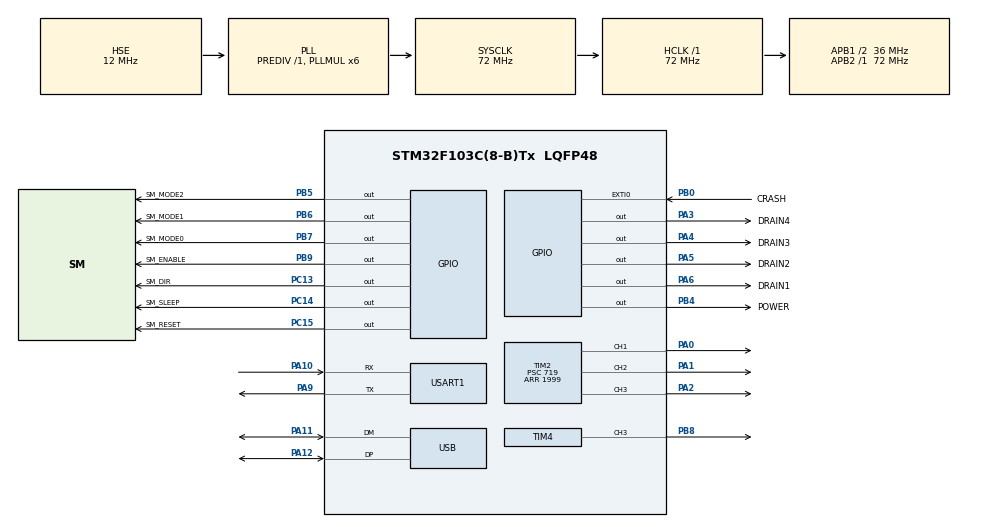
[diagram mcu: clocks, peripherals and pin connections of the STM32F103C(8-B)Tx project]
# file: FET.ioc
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Mcu.Family=STM32F1
Mcu.Name=STM32F103C(8-B)Tx
Mcu.Package=LQFP48
NVIC.EXTI0_IRQn=true\:2\:0\:true\:false\:true
NVIC.PriorityGroup=NVIC_PRIORITYGROUP_4
NVIC.TIM4_IRQn=true\:0\:0\:false\:false\:true
NVIC.USB_LP_CAN1_RX0_IRQn=true\:0\:0\:false\:false\:true
PA0-WKUP.Signal=S_TIM2_CH1_ETR
PA1.Signal=S_TIM2_CH2
PA10.Mode=Asynchronous
PA10.Signal=USART1_RX
PA11.Mode=Device
PA11.Signal=USB_DM
PA12.Mode=Device
PA12.Signal=USB_DP
PA13.Mode=Serial_Wire
PA13.Signal=SYS_JTMS-SWDIO
PA14.Mode=Serial_Wire
PA14.Signal=SYS_JTCK-SWCLK
PA2.Signal=S_TIM2_CH3
PA3.GPIO_Label=DRAIN4
PA3.Signal=GPIO_Output
PA4.GPIO_Label=DRAIN3
PA4.Signal=GPIO_Output
PA5.GPIO_Label=DRAIN2
PA5.Signal=GPIO_Output
PA6.GPIO_Label=DRAIN1
PA6.Signal=GPIO_Output
PA9.Mode=Asynchronous
PA9.Signal=USART1_TX
PB0.GPIO_Label=CRASH
PB0.GPIO_ModeDefaultEXTI=GPIO_MODE_IT_FALLING
PB0.GPIO_PuPd=GPIO_PULLUP
PB0.Signal=GPXTI0
PB4.GPIO_Label=POWER
PB4.Signal=GPIO_Output
PB5.GPIO_Label=SM_MODE2
PB5.Signal=GPIO_Output
PB6.GPIO_Label=SM_MODE1
PB6.Signal=GPIO_Output
PB7.GPIO_Label=SM_MODE0
PB7.Signal=GPIO_Output
PB8.Signal=S_TIM4_CH3
PB9.GPIO_Label=SM_ENABLE
PB9.Signal=GPIO_Output
PC13-TAMPER-RTC.GPIO_Label=SM_DIR
PC13-TAMPER-RTC.Signal=GPIO_Output
PC14-OSC32_IN.GPIO_Label=SM_SLEEP
PC14-OSC32_IN.Signal=GPIO_Output
PC15-OSC32_OUT.GPIO_Label=SM_RESET
PC15-OSC32_OUT.Signal=GPIO_Output
PD0-OSC_IN.Mode=HSE-External-Oscillator
PD0-OSC_IN.Signal=RCC_OSC_IN
PD1-OSC_OUT.Mode=HSE-External-Oscillator
PD1-OSC_OUT.Signal=RCC_OSC_OUT
ProjectManager.HeapSize=0x200
ProjectManager.StackSize=0x400
ProjectManager.TargetToolchain=MDK-ARM V5
RCC.AHBFreq_Value=72000000
RCC.APB1CLKDivider=RCC_HCLK_DIV2
RCC.APB1Freq_Value=36000000
RCC.APB1TimFreq_Value=72000000
RCC.APB2Freq_Value=72000000
RCC.APB2TimFreq_Value=72000000
RCC.HCLKFreq_Value=72000000
RCC.HSE_VALUE=12000000
RCC.HSIState=RCC_HSI_ON
RCC.PLLMUL=RCC_PLL_MUL6
RCC.SYSCLKFreq_VALUE=72000000
RCC.SYSCLKSource=RCC_SYSCLKSOURCE_PLLCLK
RCC.USBFreq_Value=48000000
RCC.USBPrescaler=RCC_USBCLKSOURCE_PLL_DIV1_5
RCC.VDD_VALUE=3.3
SH.S_TIM2_CH1_ETR.0=TIM2_CH1,PWM Generation1 CH1
SH.S_TIM2_CH2.0=TIM2_CH2,PWM Generation2 CH2
SH.S_TIM2_CH3.0=TIM2_CH3,PWM Generation3 CH3
SH.S_TIM4_CH3.0=TIM4_CH3,PWM Generation3 CH3
TIM2.Channel-PWM\ Generation2\ CH2=TIM_CHANNEL_2
TIM2.Channel-PWM\ Generation3\ CH3=TIM_CHANNEL_3
TIM2.Period=1999
TIM2.Prescaler=719
TIM2.Pulse-PWM\ Generation1\ CH1=150
TIM2.Pulse-PWM\ Generation2\ CH2=150
TIM2.Pulse-PWM\ Generation3\ CH3=150
TIM4.Channel-PWM\ Generation3\ CH3=TIM_CHANNEL_3
TIM4.Period=399
TIM4.Prescaler=71
TIM4.Pulse-PWM\ Generation3\ CH3=20
USB.ep0_mps=DEP0CTL_MPS_64
USB_DEVICE.CLASS_NAME_FS=CDC
USB_DEVICE.USBD_HandleTypeDef=hUsbDeviceFS
USB_DEVICE.VirtualMode=Cdc
USB_DEVICE.VirtualModeFS=Cdc_FS
VP_USB_DEVICE_VS_USB_DEVICE_CDC_FS.Mode=CDC_FS
board=FET

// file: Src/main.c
/**
  ******************************************************************************
  * File Name          : main.c
  * Description        : Main program body
  ******************************************************************************
  *
  * COPYRIGHT(c) 2017 STMicroelectronics
  *
  * Redistribution and use in source and binary forms, with or without modification,
  * are permitted provided that the following conditions are met:
  *   1. Redistributions of source code must retain the above copyright notice,
  *      this list of conditions and the following disclaimer.
  *   2. Redistributions in binary form must reproduce the above copyright notice,
  *      this list of conditions and the following disclaimer in the documentation
  *      and/or other materials provided with the distribution.
  *   3. Neither the name of STMicroelectronics nor the names of its contributors
  *      may be used to endorse or promote products derived from this software
  *      without specific prior written permission.
  *
  * THIS SOFTWARE IS PROVIDED BY THE COPYRIGHT HOLDERS AND CONTRIBUTORS "AS IS"
  * AND ANY EXPRESS OR IMPLIED WARRANTIES, INCLUDING, BUT NOT LIMITED TO, THE
  * IMPLIED WARRANTIES OF MERCHANTABILITY AND FITNESS FOR A PARTICULAR PURPOSE ARE
  * DISCLAIMED. IN NO EVENT SHALL THE COPYRIGHT HOLDER OR CONTRIBUTORS BE LIABLE
  * FOR ANY DIRECT, INDIRECT, INCIDENTAL, SPECIAL, EXEMPLARY, OR CONSEQUENTIAL
  * DAMAGES (INCLUDING, BUT NOT LIMITED TO, PROCUREMENT OF SUBSTITUTE GOODS OR
  * SERVICES; LOSS OF USE, DATA, OR PROFITS; OR BUSINESS INTERRUPTION) HOWEVER
  * CAUSED AND ON ANY THEORY OF LIABILITY, WHETHER IN CONTRACT, STRICT LIABILITY,
  * OR TORT (INCLUDING NEGLIGENCE OR OTHERWISE) ARISING IN ANY WAY OUT OF THE USE
  * OF THIS SOFTWARE, EVEN IF ADVISED OF THE POSSIBILITY OF SUCH DAMAGE.
  *
  ******************************************************************************
  */
#include "stm32f1xx_hal.h"
#include "usb_device.h"

/* USER CODE BEGIN Includes */
#include "sys.h"
#include "stepmotor.h"
#include "sterringengine.h"
#include "DrainSelect.h"
/* USER CODE END Includes */

TIM_HandleTypeDef htim2;
TIM_HandleTypeDef htim4;

UART_HandleTypeDef huart1;

/* USER CODE BEGIN PV */
/* Private variables ---------------------------------------------------------*/

/* USER CODE END PV */

void SystemClock_Config(void);
void Error_Handler(void);
static void MX_GPIO_Init(void);
static void MX_TIM2_Init(void);
static void MX_TIM4_Init(void);
static void MX_USART1_UART_Init(void);

void HAL_TIM_MspPostInit(TIM_HandleTypeDef *htim);

/* USER CODE BEGIN PFP */
/* Private function prototypes -----------------------------------------------*/

/* USER CODE END PFP */

int main(void)
{

  /* MCU Configuration----------------------------------------------------------*/

  /* Reset of all peripherals, Initializes the Flash interface and the Systick. */
  HAL_Init();

  /* Configure the system clock */
  SystemClock_Config();

  /* Initialize all configured peripherals */
  MX_GPIO_Init();
  MX_TIM2_Init();
  MX_TIM4_Init();
  MX_USART1_UART_Init();
  MX_USB_DEVICE_Init();

  /* USER CODE BEGIN 2 */
  stepmotor_init();
  sterringengine_init();
  drain_disconnect_all();
  /* USER CODE END 2 */

  /* Infinite loop */
  /* USER CODE BEGIN WHILE */
  u8 rxbuffer[5] = {0};
  int temp_steps = 0;
  while (1)
  {

  /*  HAL_UART_Receive(&huart1,rxbuffer,5,1000);
    sterringengine_rotate(SE_CH1,(u32)rxbuffer[0]);
    temp_steps = (int)((rxbuffer[1]<<24)|(rxbuffer[2]<<16)|(rxbuffer[3]<<8)|rxbuffer[4]);
    stepmotor_step(temp_steps);
    printf("%d %d %d\r\n",temp_steps,stepmotor_get_current_step(),stepmotor_get_busy_flag());
    for(u8 i=1;i!=5;i++){
      rxbuffer[i] = 0;
    }                         */
  /* USER CODE END WHILE */

  }

}

/** System Clock Configuration
*/
void SystemClock_Config(void)
{

  RCC_OscInitTypeDef RCC_OscInitStruct;
  RCC_ClkInitTypeDef RCC_ClkInitStruct;
  RCC_PeriphCLKInitTypeDef PeriphClkInit;

  RCC_OscInitStruct.OscillatorType = RCC_OSCILLATORTYPE_HSE;
  RCC_OscInitStruct.HSEState = RCC_HSE_ON;
  RCC_OscInitStruct.HSEPredivValue = RCC_HSE_PREDIV_DIV1;
  RCC_OscInitStruct.PLL.PLLState = RCC_PLL_ON;
  RCC_OscInitStruct.PLL.PLLSource = RCC_PLLSOURCE_HSE;
  RCC_OscInitStruct.PLL.PLLMUL = RCC_PLL_MUL6;
  if (HAL_RCC_OscConfig(&RCC_OscInitStruct) != HAL_OK)
  {
    Error_Handler();
  }

  RCC_ClkInitStruct.ClockType = RCC_CLOCKTYPE_HCLK|RCC_CLOCKTYPE_SYSCLK
                              |RCC_CLOCKTYPE_PCLK1|RCC_CLOCKTYPE_PCLK2;
  RCC_ClkInitStruct.SYSCLKSource = RCC_SYSCLKSOURCE_PLLCLK;
  RCC_ClkInitStruct.AHBCLKDivider = RCC_SYSCLK_DIV1;
  RCC_ClkInitStruct.APB1CLKDivider = RCC_HCLK_DIV2;
  RCC_ClkInitStruct.APB2CLKDivider = RCC_HCLK_DIV1;
  if (HAL_RCC_ClockConfig(&RCC_ClkInitStruct, FLASH_LATENCY_2) != HAL_OK)
  {
    Error_Handler();
  }

  PeriphClkInit.PeriphClockSelection = RCC_PERIPHCLK_USB;
  PeriphClkInit.UsbClockSelection = RCC_USBCLKSOURCE_PLL_DIV1_5;
  if (HAL_RCCEx_PeriphCLKConfig(&PeriphClkInit) != HAL_OK)
  {
    Error_Handler();
  }

  HAL_SYSTICK_Config(HAL_RCC_GetHCLKFreq()/1000);

  HAL_SYSTICK_CLKSourceConfig(SYSTICK_CLKSOURCE_HCLK);

  /* SysTick_IRQn interrupt configuration */
  HAL_NVIC_SetPriority(SysTick_IRQn, 0, 0);
}

/* TIM2 init function */
static void MX_TIM2_Init(void)
{

  TIM_MasterConfigTypeDef sMasterConfig;
  TIM_OC_InitTypeDef sConfigOC;

  htim2.Instance = TIM2;
  htim2.Init.Prescaler = 719;
  htim2.Init.CounterMode = TIM_COUNTERMODE_UP;
  htim2.Init.Period = 1999;
  htim2.Init.ClockDivision = TIM_CLOCKDIVISION_DIV1;
  if (HAL_TIM_PWM_Init(&htim2) != HAL_OK)
  {
    Error_Handler();
  }

  sMasterConfig.MasterOutputTrigger = TIM_TRGO_RESET;
  sMasterConfig.MasterSlaveMode = TIM_MASTERSLAVEMODE_DISABLE;
  if (HAL_TIMEx_MasterConfigSynchronization(&htim2, &sMasterConfig) != HAL_OK)
  {
    Error_Handler();
  }

  sConfigOC.OCMode = TIM_OCMODE_PWM1;
  sConfigOC.Pulse = 150;
  sConfigOC.OCPolarity = TIM_OCPOLARITY_HIGH;
  sConfigOC.OCFastMode = TIM_OCFAST_DISABLE;
  if (HAL_TIM_PWM_ConfigChannel(&htim2, &sConfigOC, TIM_CHANNEL_1) != HAL_OK)
  {
    Error_Handler();
  }

  if (HAL_TIM_PWM_ConfigChannel(&htim2, &sConfigOC, TIM_CHANNEL_2) != HAL_OK)
  {
    Error_Handler();
  }

  if (HAL_TIM_PWM_ConfigChannel(&htim2, &sConfigOC, TIM_CHANNEL_3) != HAL_OK)
  {
    Error_Handler();
  }

  HAL_TIM_MspPostInit(&htim2);

}

/* TIM4 init function */
static void MX_TIM4_Init(void)
{

  TIM_MasterConfigTypeDef sMasterConfig;
  TIM_OC_InitTypeDef sConfigOC;

  htim4.Instance = TIM4;
  htim4.Init.Prescaler = 71;
  htim4.Init.CounterMode = TIM_COUNTERMODE_UP;
  htim4.Init.Period = 399;
  htim4.Init.ClockDivision = TIM_CLOCKDIVISION_DIV1;
  if (HAL_TIM_PWM_Init(&htim4) != HAL_OK)
  {
    Error_Handler();
  }

  sMasterConfig.MasterOutputTrigger = TIM_TRGO_RESET;
  sMasterConfig.MasterSlaveMode = TIM_MASTERSLAVEMODE_DISABLE;
  if (HAL_TIMEx_MasterConfigSynchronization(&htim4, &sMasterConfig) != HAL_OK)
  {
    Error_Handler();
  }

  sConfigOC.OCMode = TIM_OCMODE_PWM1;
  sConfigOC.Pulse = 20;
  sConfigOC.OCPolarity = TIM_OCPOLARITY_HIGH;
  sConfigOC.OCFastMode = TIM_OCFAST_DISABLE;
  if (HAL_TIM_PWM_ConfigChannel(&htim4, &sConfigOC, TIM_CHANNEL_3) != HAL_OK)
  {
    Error_Handler();
  }

  HAL_TIM_MspPostInit(&htim4);

}

/* USART1 init function */
static void MX_USART1_UART_Init(void)
{

  huart1.Instance = USART1;
  huart1.Init.BaudRate = 115200;
  huart1.Init.WordLength = UART_WORDLENGTH_8B;
  huart1.Init.StopBits = UART_STOPBITS_1;
  huart1.Init.Parity = UART_PARITY_NONE;
  huart1.Init.Mode = UART_MODE_TX_RX;
  huart1.Init.HwFlowCtl = UART_HWCONTROL_NONE;
  huart1.Init.OverSampling = UART_OVERSAMPLING_16;
  if (HAL_UART_Init(&huart1) != HAL_OK)
  {
    Error_Handler();
  }

}

/** Configure pins as
        * Analog
        * Input
        * Output
        * EVENT_OUT
        * EXTI
*/
static void MX_GPIO_Init(void)
{

  GPIO_InitTypeDef GPIO_InitStruct;

  /* GPIO Ports Clock Enable */
  __HAL_RCC_GPIOC_CLK_ENABLE();
  __HAL_RCC_GPIOD_CLK_ENABLE();
  __HAL_RCC_GPIOA_CLK_ENABLE();
  __HAL_RCC_GPIOB_CLK_ENABLE();

  /*Configure GPIO pin Output Level */
  HAL_GPIO_WritePin(GPIOC, SM_DIR_Pin|SM_SLEEP_Pin|SM_RESET_Pin, GPIO_PIN_RESET);

  /*Configure GPIO pin Output Level */
  HAL_GPIO_WritePin(GPIOA, DRAIN4_Pin|DRAIN3_Pin|DRAIN2_Pin|DRAIN1_Pin, GPIO_PIN_RESET);

  /*Configure GPIO pin Output Level */
  HAL_GPIO_WritePin(GPIOB, POWER_Pin|SM_MODE2_Pin|SM_MODE1_Pin|SM_MODE0_Pin
                          |SM_ENABLE_Pin, GPIO_PIN_RESET);

  /*Configure GPIO pins : SM_DIR_Pin SM_SLEEP_Pin SM_RESET_Pin */
  GPIO_InitStruct.Pin = SM_DIR_Pin|SM_SLEEP_Pin|SM_RESET_Pin;
  GPIO_InitStruct.Mode = GPIO_MODE_OUTPUT_PP;
  GPIO_InitStruct.Speed = GPIO_SPEED_FREQ_LOW;
  HAL_GPIO_Init(GPIOC, &GPIO_InitStruct);

  /*Configure GPIO pins : DRAIN4_Pin DRAIN3_Pin DRAIN2_Pin DRAIN1_Pin */
  GPIO_InitStruct.Pin = DRAIN4_Pin|DRAIN3_Pin|DRAIN2_Pin|DRAIN1_Pin;
  GPIO_InitStruct.Mode = GPIO_MODE_OUTPUT_PP;
  GPIO_InitStruct.Speed = GPIO_SPEED_FREQ_LOW;
  HAL_GPIO_Init(GPIOA, &GPIO_InitStruct);

  /*Configure GPIO pin : CRASH_Pin */
  GPIO_InitStruct.Pin = CRASH_Pin;
  GPIO_InitStruct.Mode = GPIO_MODE_IT_FALLING;
  GPIO_InitStruct.Pull = GPIO_PULLUP;
  HAL_GPIO_Init(CRASH_GPIO_Port, &GPIO_InitStruct);

  /*Configure GPIO pins : POWER_Pin SM_MODE2_Pin SM_MODE1_Pin SM_MODE0_Pin
                           SM_ENABLE_Pin */
  GPIO_InitStruct.Pin = POWER_Pin|SM_MODE2_Pin|SM_MODE1_Pin|SM_MODE0_Pin
                          |SM_ENABLE_Pin;
  GPIO_InitStruct.Mode = GPIO_MODE_OUTPUT_PP;
  GPIO_InitStruct.Speed = GPIO_SPEED_FREQ_LOW;
  HAL_GPIO_Init(GPIOB, &GPIO_InitStruct);

  /* EXTI interrupt init*/
  HAL_NVIC_SetPriority(EXTI0_IRQn, 2, 0);
  HAL_NVIC_EnableIRQ(EXTI0_IRQn);

}

void Error_Handler(void)
{
  while(1)
  {
  }
}

/************************ (C) COPYRIGHT STMicroelectronics *****END OF FILE****/
